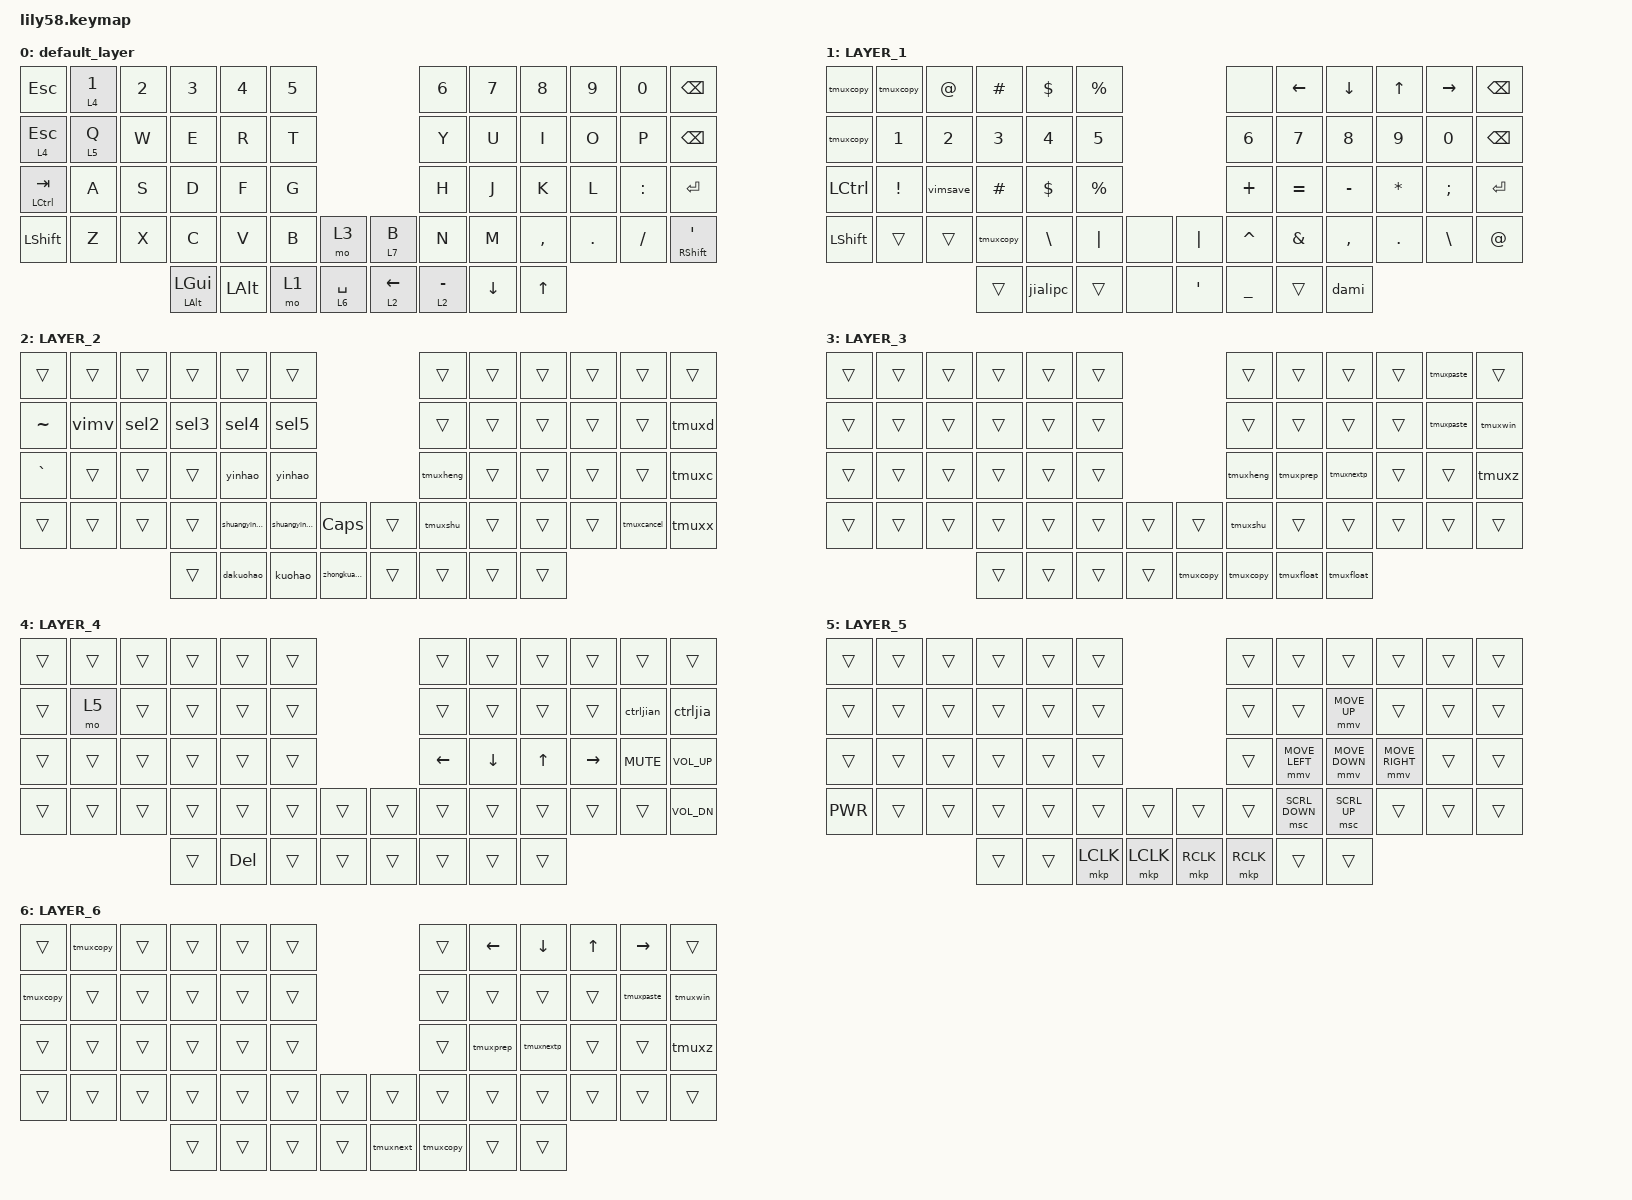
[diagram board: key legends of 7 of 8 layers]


#include <behaviors.dtsi>
#include <dt-bindings/zmk/keys.h>
#include <dt-bindings/zmk/bt.h>
#include <dt-bindings/zmk/ext_power.h>
#include <dt-bindings/zmk/rgb.h>

#define ZMK_POINTING_DEFAULT_MOVE_VAL 1200  // default: 600
#define ZMK_POINTING_DEFAULT_SCRL_VAL 20    // default: 10

#include <dt-bindings/zmk/pointing.h>
/ {
    behaviors {
        vimsave: vimsave {
            compatible = "zmk,behavior-macro";
            #binding-cells = <0>;
            bindings = < &kp ESC &kp COLON &kp W &kp RET >;
        };
        jialipc: jialipc {
            compatible = "zmk,behavior-macro";
            #binding-cells = <0>;
            bindings = < &kp N4 &kp N9 &kp N6 &kp N2 >;
        };
        dami: dami {
            compatible = "zmk,behavior-macro";
            #binding-cells = <0>;
            bindings = < &macro_press &kp LSHFT &macro_tap &kp B &macro_release &kp LSHFT &kp U &kp Z &kp H &kp I &kp D &kp A &kp O &kp N9 &kp N7 &kp N1 &kp N0 &kp N6 &kp N2 &kp N6 &kp N2 >;
        };
        tmuxshang: tmuxshang {
            compatible = "zmk,behavior-macro";
            #binding-cells = <0>;
            bindings = < &kp GRAVE &kp UP >;
        };
        tmuxxia: tmuxxia {
            compatible = "zmk,behavior-macro";
            #binding-cells = <0>;
            bindings = < &kp GRAVE &kp DOWN >;
        };
        tmuxzuo: tmuxzuo {
            compatible = "zmk,behavior-macro";
            #binding-cells = <0>;
            bindings = < &kp GRAVE &kp LEFT >;
        };
        tmuxyou: tmuxyou {
            compatible = "zmk,behavior-macro";
            #binding-cells = <0>;
            bindings = < &kp GRAVE &kp RIGHT >;
        };
        tmuxnextp: tmuxnextp {
            compatible = "zmk,behavior-macro";
            #binding-cells = <0>;
            bindings = < &kp GRAVE &kp O >;
        };
        tmuxd: tmuxd {
            compatible = "zmk,behavior-macro";
            #binding-cells = <0>;
            bindings = < &kp GRAVE &kp D >;
        };
        tmuxz: tmuxz {
            compatible = "zmk,behavior-macro";
            #binding-cells = <0>;
            bindings = < &kp GRAVE &kp Z >;
        };

        tmuxfloat: tmuxfloat {
            compatible = "zmk,behavior-macro";
            #binding-cells = <0>;
            bindings = < &kp GRAVE &kp P >;
        };
        tmuxc: tmuxc {
            compatible = "zmk,behavior-macro";
            #binding-cells = <0>;
            bindings = < &kp GRAVE &kp C >;
        };
        tmuxx: tmuxx {
            compatible = "zmk,behavior-macro";
            #binding-cells = <0>;
            bindings = < &kp GRAVE &kp X >;
        };
        tmuxcancel: tmuxcancel {
            compatible = "zmk,behavior-macro";
            #binding-cells = <0>;
            bindings = <
                &macro_press   &kp LCTRL
                &macro_tap     &kp LBKT
                &macro_release &kp LCTRL
            >;
        };
        tmuxwin: tmuxwin {
            compatible = "zmk,behavior-macro";
            #binding-cells = <0>;
            bindings = < &kp GRAVE &kp S >;
        };
        tmuxcopy: tmuxcopy {
            compatible = "zmk,behavior-macro";
            #binding-cells = <0>;
            bindings = < &kp GRAVE &kp LS(F) >;
        };
        tmuxpaste: tmuxpaste {
            compatible = "zmk,behavior-macro";
            #binding-cells = <0>;
            bindings = < &kp GRAVE &kp RBKT >;
        };
        tmuxprep: tmuxprep {
            compatible = "zmk,behavior-macro";
            #binding-cells = <0>;
            bindings = < &kp GRAVE &kp SEMI >;
        };
        tmuxnext: tmuxnext {
            compatible = "zmk,behavior-macro";
            #binding-cells = <0>;
            bindings = < &kp GRAVE &kp N >;
        };
        tmuxheng: tmuxheng {
            compatible = "zmk,behavior-macro";
            #binding-cells = <0>;
            bindings = < &kp GRAVE &kp PRCNT >;
        };
        tmuxshu: tmuxshu {
            compatible = "zmk,behavior-macro";
            #binding-cells = <0>;
            bindings = < &kp GRAVE &kp DQT >;
        };

        zhongkuahao: zhongkuahao {
            compatible = "zmk,behavior-macro";
            #binding-cells = <0>;
            bindings = < &kp LBKT &kp RBKT &kp LEFT >;
        };
        dakuohao: dakuohao {
            compatible = "zmk,behavior-macro";
            #binding-cells = <0>;
            bindings = < &kp LBRC &kp RBRC &kp LEFT >;
        };
        kuohao: kuohao {
            compatible = "zmk,behavior-macro";
            #binding-cells = <0>;
            bindings = < &kp LPAR &kp RPAR &kp LEFT >;
        };
        yinhao: yinhao {
            compatible = "zmk,behavior-macro";
            #binding-cells = <0>;
            bindings = < &kp APOS &kp APOS &kp LEFT >;
        };
        shuangyinhao: shuangyinhao {
            compatible = "zmk,behavior-macro";
            #binding-cells = <0>;
            bindings = < &kp DQT &kp DQT &kp LEFT >;
        };

        vimv: vimv {
            compatible = "zmk,behavior-macro";
            #binding-cells = <0>;
            bindings = < &kp N0 &kp V &kp DLLR >;
        };
        sel1: sel1 {
            compatible = "zmk,behavior-macro";
            #binding-cells = <0>;
            bindings = < &kp N1 &kp J &kp DLLR >;
        };
        sel2: sel2 {
            compatible = "zmk,behavior-macro";
            #binding-cells = <0>;
            bindings = < &kp N2 &kp J &kp DLLR >;
        };
        sel3: sel3 {
            compatible = "zmk,behavior-macro";
            #binding-cells = <0>;
            bindings = < &kp N3 &kp J &kp DLLR >;
        };
        sel4: sel4 {
            compatible = "zmk,behavior-macro";
            #binding-cells = <0>;
            bindings = < &kp N4 &kp J &kp DLLR >;
        };
        sel5: sel5 {
            compatible = "zmk,behavior-macro";
            #binding-cells = <0>;
            bindings = < &kp N5 &kp J &kp DLLR >;
        };

        ctrljian: ctrljian {
            compatible = "zmk,behavior-macro";
            #binding-cells = <0>;
            bindings = <
                &macro_press   &kp LCTRL
                &macro_tap     &kp MINUS 
                &macro_release &kp LCTRL
            >;
        };
        ctrljia: ctrljia {
            compatible = "zmk,behavior-macro";
            #binding-cells = <0>;
            bindings = <
                &macro_press   &kp LCTRL
                &macro_tap     &kp PLUS
                &macro_release &kp LCTRL
            >;
        };


    };
                
                
                




    
    keymap {
        compatible = "zmk,keymap";

        default_layer {
        //===============================================================================================================================
        bindings = <
            // ------------------------------------------------------------------------------------------------------------
            &kp ESC       &lt 4 N1  &kp N2 &kp N3        &kp N4   &kp N5                            &kp N6      &kp N7   &kp N8    &kp N9  &kp N0    &kp BSPC
            &lt 4 ESC     &lt 5 Q   &kp W  &kp E         &kp R    &kp T                             &kp Y       &kp U    &kp I     &kp O   &kp P     &kp BSPC
            &mt LCTRL TAB &kp A     &kp S  &kp D         &kp F    &kp G                             &kp H       &kp J    &kp K     &kp L   &kp COLON &kp RET
            &kp LSHFT     &kp Z     &kp X  &kp C         &kp V    &kp B  &mo 3          &lt 7 B     &kp N       &kp M    &kp COMMA &kp DOT &kp FSLH  &mt RSHFT SQT
                                           &mt LALT LGUI &kp LALT &mo 1  &lt 6 SPACE    &lt 2 LEFT  &lt 2 MINUS &kp DOWN &kp UP  
            // ------------------------------------------------------------------------------------------------------------
        >; };
        //===============================================================================================================================


        LAYER_1 {
        bindings = <
            // ------------------------------------------------------------------------------------------------------------
            &tmuxcopy   &tmuxcopy     &kp AT       &kp HASH         &kp DLLR   &kp PRCNT                          &none        &kp LEFT   &kp DOWN   &kp UP    &kp RIGHT &kp BSPC
            &tmuxcopy   &kp N1        &kp N2       &kp N3           &kp N4     &kp N5                             &kp N6       &kp N7     &kp N8     &kp N9    &kp N0    &kp BSPC
            &kp LCTRL   &kp EXCL      &vimsave     &kp HASH         &kp DLLR   &kp PRCNT                          &kp PLUS     &kp EQUAL  &kp MINUS  &kp STAR  &kp SEMI  &kp RET
            &kp LSHFT   &trans        &trans       &tmuxcopy        &kp BSLH   &kp PIPE  &none        &kp PIPE    &kp CARET    &kp AMPS   &kp COMMA  &kp DOT   &kp BSLH  &kp AT
                                                   &trans           &jialipc   &trans    &none        &kp SQT     &kp UNDER    &trans     &dami
            // ------------------------------------------------------------------------------------------------------------
        >; };
        //===============================================================================================================================

        LAYER_2 {
        bindings = <
            // ------------------------------------------------------------------------------------------------------------
            &trans      &trans    &trans       &trans           &trans        &trans                                  &trans       &trans     &trans     &trans    &trans         &trans
            &kp TILDE   &vimv     &sel2        &sel3            &sel4         &sel5                                   &trans       &trans     &trans     &trans    &trans         &tmuxd
            &kp GRAVE   &trans    &trans       &trans           &yinhao       &yinhao                                 &tmuxheng    &trans     &trans     &trans    &trans         &tmuxc
            &trans      &trans    &trans       &trans           &shuangyinhao &shuangyinhao  &kp CAPS        &trans   &tmuxshu     &trans     &trans     &trans    &tmuxcancel    &tmuxx
                                               &trans           &dakuohao     &kuohao        &zhongkuahao    &trans   &trans       &trans     &trans
            // ------------------------------------------------------------------------------------------------------------
        >; };
        //===============================================================================================================================

        LAYER_3 {
        bindings = <
            // ------------------------------------------------------------------------------------------------------------
            &trans      &trans    &trans       &trans           &trans     &trans                              &trans       &trans     &trans     &trans    &tmuxpaste    &trans
            &trans      &trans    &trans       &trans           &trans     &trans                              &trans       &trans     &trans     &trans    &tmuxpaste    &tmuxwin
            &trans      &trans    &trans       &trans           &trans     &trans                              &tmuxheng    &tmuxprep  &tmuxnextp &trans    &trans        &tmuxz
            &trans      &trans    &trans       &trans           &trans     &trans  &trans        &trans        &tmuxshu     &trans     &trans     &trans    &trans        &trans
                                               &trans           &trans     &trans  &trans        &tmuxcopy     &tmuxcopy    &tmuxfloat     &tmuxfloat
            // ------------------------------------------------------------------------------------------------------------
        >; };
        //===============================================================================================================================

        LAYER_4 {
        bindings = <
            // ------------------------------------------------------------------------------------------------------------
            &trans      &trans    &trans       &trans           &trans     &trans                              &trans       &trans     &trans     &trans    &trans     &trans
            &trans      &mo 5     &trans       &trans           &trans     &trans                              &trans       &trans     &trans     &trans    &ctrljian  &ctrljia
            &trans      &trans    &trans       &trans           &trans     &trans                              &kp LEFT     &kp DOWN   &kp UP     &kp RIGHT &kp C_MUTE &kp C_VOL_UP
            &trans      &trans    &trans       &trans           &trans     &trans  &trans        &trans        &trans       &trans     &trans     &trans    &trans     &kp C_VOL_DN
                                               &trans           &kp DEL    &trans  &trans        &trans        &trans       &trans     &trans
            // ------------------------------------------------------------------------------------------------------------
        >; };

        //===============================================================================================================================

        LAYER_5 {
        bindings = <
            // ------------------------------------------------------------------------------------------------------------
            &trans      &trans    &trans       &trans           &trans     &trans                                &trans       &trans           &trans             &trans           &trans    &trans
            &trans      &trans    &trans       &trans           &trans     &trans                                &trans       &trans           &mmv MOVE_UP       &trans           &trans    &trans
            &trans      &trans    &trans       &trans           &trans     &trans                                &trans       &mmv MOVE_LEFT   &mmv MOVE_DOWN     &mmv MOVE_RIGHT  &trans    &trans
            &kp C_PWR   &trans    &trans       &trans           &trans     &trans    &trans           &trans     &trans       &msc SCRL_DOWN   &msc SCRL_UP       &trans           &trans    &trans
                                               &trans           &trans     &mkp LCLK &mkp LCLK        &mkp RCLK  &mkp RCLK       &trans           &trans
            // ------------------------------------------------------------------------------------------------------------
        >; };


        //===============================================================================================================================
        LAYER_6 {
        bindings = <
            // ------------------------------------------------------------------------------------------------------------
            &trans      &tmuxcopy &trans       &trans           &trans     &trans                              &trans       &kp LEFT   &kp DOWN    &kp UP    &kp RIGHT   &trans
            &tmuxcopy   &trans    &trans       &trans           &trans     &trans                              &trans       &trans     &trans      &trans    &tmuxpaste  &tmuxwin
            &trans      &trans    &trans       &trans           &trans     &trans                              &trans       &tmuxprep  &tmuxnextp  &trans    &trans      &tmuxz
            &trans      &trans    &trans       &trans           &trans     &trans  &trans        &trans        &trans       &trans     &trans      &trans    &trans      &trans
                                               &trans           &trans     &trans  &trans        &tmuxnext     &tmuxcopy    &trans     &trans
            // ------------------------------------------------------------------------------------------------------------
        >; };
        //===============================================================================================================================


        //===============================================================================================================================
     //   LAYER_7 {
     //   bindings = <
            // ------------------------------------------------------------------------------------------------------------
    //        &trans      &trans    &trans       &trans           &trans     &trans                              &trans       &trans     &trans     &trans    &trans    &trans
    //        &trans      &trans    &trans       &trans           &trans     &trans                              &trans       &trans     &trans     &trans    &trans    &trans
    //        &trans      &trans    &trans       &trans           &trans     &trans                              &trans       &trans     &trans     &trans    &trans    &trans
    //        &trans      &trans    &trans       &trans           &trans     &trans  &trans        &trans        &trans       &trans     &trans     &trans    &trans    &trans
    //                                           &trans           &trans     &trans  &trans        &trans        &trans       &trans     &trans
            // ------------------------------------------------------------------------------------------------------------
    //    >; };
        //===============================================================================================================================


        adjust_layer {
// ----------------------------------------------------------------------------------------------------------------------------
// | BTCLR  |  BT1    |  BT2    |   BT3   |   BT4   |   BT5   |                  |      |      |       |      |       |       |
// | EXTPWR | RGB_HUD | RGB_HUI | RGB_SAD | RGB_SAI | RGB_EFF |                  |      |      |       |      |       |       |
// |        | RGB_BRD | RGB_BRI |         |         |         |                  |      |      |       |      |       |       |
// |        |         |         |         |         |         | RGB_TOG | |      |      |      |       |      |       |       |
//                    |         |         |         |         |         | |      |      |      |       |      |
            bindings = <
                &bt BT_CLR        &bt BT_SEL 0    &bt BT_SEL 1    &bt BT_SEL 2    &bt BT_SEL 3    &bt BT_SEL 4                            &trans &trans &trans &trans &trans &trans
                &bt BT_CLR        &bt BT_SEL 0    &bt BT_SEL 1    &bt BT_SEL 2    &bt BT_SEL 3    &bt BT_SEL 4                         &trans &trans &trans &trans &trans &trans
                &trans            &trans          &trans          &trans          &trans           &trans                                   &trans &trans &trans &trans &trans &trans
                &trans            &trans          &trans          &trans          &trans           &trans            &trans &trans  &trans &trans &trans &trans &trans &trans
                                                  &trans          &trans          &trans           &trans            &trans           &trans  &trans &trans &trans &trans
            >;
        };
        extra1 { status = "reserved"; };

        extra2 { status = "reserved"; };

        extra3 { status = "reserved"; };

        extra4 { status = "reserved"; };

        extra5 { status = "reserved"; };
    };
};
